AUTOSAR XML (schema 00051)
package /TPC_Composition/Components
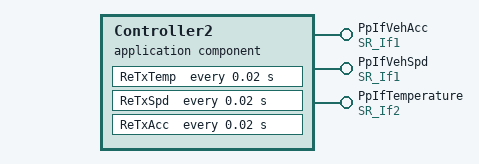
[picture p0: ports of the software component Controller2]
  application sw component type Controller2
    provide port PpIfVehAcc: provided-interface=SR_If1, nonqueued-sender-com-spec{data-element=Acc, init-value=777}
    provide port PpIfVehSpd: provided-interface=SR_If1, nonqueued-sender-com-spec{data-element=Spd, init-value=666}
    provide port PpIfTemperature: provided-interface=SR_If2, queued-sender-com-spec=Temp
    behavior SWC_Controller2_InternalBehavior: supports-multiple-instantiation=true
      runnable ReTxTemp
        data-write-access:
          access DataSendPoint_PpIfTemperature_Temp: return-value-provision=RETURN-VALUE-PROVIDED, accessed-variable=PpIfTemperature.Temp
      runnable ReTxSpd
        data-write-access:
          access DataSendPoint_PpIfVehMov_Spd: return-value-provision=RETURN-VALUE-PROVIDED, accessed-variable=PpIfVehSpd.Spd
      runnable ReTxAcc
        data-write-access:
          access DataSendPoint_PpIfVehMov_Acc: return-value-provision=RETURN-VALUE-PROVIDED, accessed-variable=PpIfVehAcc.Acc
      timing event EvTiTemp_20ms: start-on-event=ReTxTemp, period=0.02
      timing event EvTiSpd_20ms: start-on-event=ReTxSpd, period=0.02
      timing event EvTiAcc_20ms: start-on-event=ReTxAcc, period=0.02
      port-api-options:
        port=PpIfVehAcc, transformer-status-forwarding=TRANSFORMER-STATUS-FORWARDING, error-handling=TRANSFORMER-ERROR-HANDLING
        port=PpIfTemperature, error-handling=TRANSFORMER-ERROR-HANDLING
